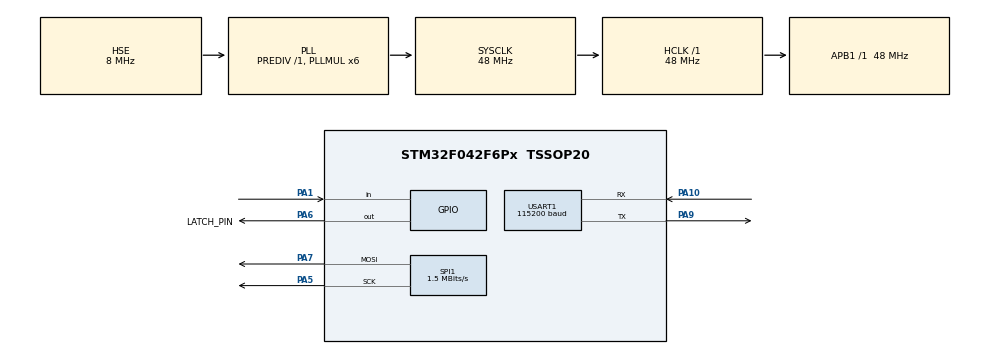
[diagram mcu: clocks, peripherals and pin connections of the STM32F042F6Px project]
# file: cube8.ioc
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Mcu.Family=STM32F0
Mcu.Name=STM32F042F6Px
Mcu.Package=TSSOP20
NVIC.USART1_IRQn=true\:0\:0\:false\:false\:true\:true\:true\:true
PA1.GPIO_PuPd=GPIO_PULLUP
PA1.Signal=GPIO_Input
PA10.Mode=Asynchronous
PA10.Signal=USART1_RX
PA13.Mode=Serial_Wire
PA13.Signal=SYS_SWDIO
PA14.Mode=Serial_Wire
PA14.Signal=SYS_SWCLK
PA5.Mode=TX_Only_Simplex_Unidirect_Master
PA5.Signal=SPI1_SCK
PA6.GPIO_Label=LATCH_PIN
PA6.GPIO_Speed=GPIO_SPEED_FREQ_HIGH
PA6.Signal=GPIO_Output
PA7.Mode=TX_Only_Simplex_Unidirect_Master
PA7.Signal=SPI1_MOSI
PA9.Mode=Asynchronous
PA9.Signal=USART1_TX
PF0-OSC_IN.Mode=HSE-External-Oscillator
PF0-OSC_IN.Signal=RCC_OSC_IN
PF1-OSC_OUT.Mode=HSE-External-Oscillator
PF1-OSC_OUT.Signal=RCC_OSC_OUT
ProjectManager.HeapSize=0x200
ProjectManager.StackSize=0x400
ProjectManager.TargetToolchain=STM32CubeIDE
RCC.AHBFreq_Value=48000000
RCC.APB1Freq_Value=48000000
RCC.APB1TimFreq_Value=48000000
RCC.HCLKFreq_Value=48000000
RCC.PLLMUL=RCC_PLL_MUL6
RCC.PLLSourceVirtual=RCC_PLLSOURCE_HSE
RCC.SYSCLKFreq_VALUE=48000000
RCC.SYSCLKSource=RCC_SYSCLKSOURCE_PLLCLK
SPI1.BaudRatePrescaler=SPI_BAUDRATEPRESCALER_32
SPI1.CalculateBaudRate=1.5 MBits/s
SPI1.DataSize=SPI_DATASIZE_8BIT
SPI1.Direction=SPI_DIRECTION_2LINES
SPI1.FirstBit=SPI_FIRSTBIT_MSB
SPI1.Mode=SPI_MODE_MASTER
SPI1.NSSPMode=SPI_NSS_PULSE_DISABLE
SPI1.VirtualType=VM_MASTER
USART1.BaudRate=115200
USART1.Mode=MODE_RX
USART1.VirtualMode=VM_ASYNC
board=custom

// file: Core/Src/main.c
#include "main.h"

/* USER CODE BEGIN Includes */

#include "led_cube_handle.h"
/* USER CODE END Includes */

/* USER CODE BEGIN PV */
SPI_HandleTypeDef hspi1;
UART_HandleTypeDef huart1;
uint8_t rxData;
Btn_Typedef button1;
/* USER CODE END PV */

void SystemClock_Config(void);
static void MX_GPIO_Init(void);
static void MX_SPI1_Init(void);
static void MX_USART1_UART_Init(void);
/* USER CODE BEGIN PFP */
void HAL_UART_RxCpltCallback(UART_HandleTypeDef *huart);
/* USER CODE END PFP */

/* USER CODE BEGIN 0 */
void HAL_UART_RxCpltCallback(UART_HandleTypeDef *huart)
{
	if (huart->Instance == huart1.Instance)
	{
		HAL_UART_Receive_IT(&huart1, &rxData, 1);
		currentEffect = rxData - 48;
	}
}
/* USER CODE END 0 */

int main(void)
{

  /* MCU Configuration--------------------------------------------------------*/

  /* Reset of all peripherals, Initializes the Flash interface and the Systick. */
  HAL_Init();

  /* USER CODE BEGIN Init */

  Btn_Init(&button1, GPIOA, GPIO_PIN_1);
  /* USER CODE END Init */

  /* Configure the system clock */
  SystemClock_Config();

  /* Initialize all configured peripherals */
  MX_GPIO_Init();
  MX_SPI1_Init();
  MX_USART1_UART_Init();
  /* USER CODE BEGIN 2 */
  HAL_UART_Receive_IT(&huart1,&rxData, 1);
  /* USER CODE END 2 */

  /* Infinite loop */
  while (1)
  {

    /* USER CODE BEGIN 3 */
	  Btn_Handle(&button1);
	  Led_cube_Handle(currentEffect);
//	  for (int i = 0; i < 8; i++)
//	  {
//		  for (int j = 0; j < 8; j++)
//		  {
//			  for (int k = 0; k < 8; k++)
//			  {
//				  DisplayLed(k, j, i, hspi1, 0);
//
//				  HAL_Delay(100);
//			  }
//		  }
//	  }
  }
  /* USER CODE END 3 */
}

void SystemClock_Config(void)
{
  RCC_OscInitTypeDef RCC_OscInitStruct = {0};
  RCC_ClkInitTypeDef RCC_ClkInitStruct = {0};
  RCC_PeriphCLKInitTypeDef PeriphClkInit = {0};

  /** Initializes the RCC Oscillators according to the specified parameters
  * in the RCC_OscInitTypeDef structure.
  */
  RCC_OscInitStruct.OscillatorType = RCC_OSCILLATORTYPE_HSE;
  RCC_OscInitStruct.HSEState = RCC_HSE_ON;
  RCC_OscInitStruct.PLL.PLLState = RCC_PLL_ON;
  RCC_OscInitStruct.PLL.PLLSource = RCC_PLLSOURCE_HSE;
  RCC_OscInitStruct.PLL.PLLMUL = RCC_PLL_MUL6;
  RCC_OscInitStruct.PLL.PREDIV = RCC_PREDIV_DIV1;
  if (HAL_RCC_OscConfig(&RCC_OscInitStruct) != HAL_OK)
  {
    Error_Handler();
  }

  /** Initializes the CPU, AHB and APB buses clocks
  */
  RCC_ClkInitStruct.ClockType = RCC_CLOCKTYPE_HCLK|RCC_CLOCKTYPE_SYSCLK
                              |RCC_CLOCKTYPE_PCLK1;
  RCC_ClkInitStruct.SYSCLKSource = RCC_SYSCLKSOURCE_PLLCLK;
  RCC_ClkInitStruct.AHBCLKDivider = RCC_SYSCLK_DIV1;
  RCC_ClkInitStruct.APB1CLKDivider = RCC_HCLK_DIV1;

  if (HAL_RCC_ClockConfig(&RCC_ClkInitStruct, FLASH_LATENCY_1) != HAL_OK)
  {
    Error_Handler();
  }
  PeriphClkInit.PeriphClockSelection = RCC_PERIPHCLK_USART1;
  PeriphClkInit.Usart1ClockSelection = RCC_USART1CLKSOURCE_PCLK1;
  if (HAL_RCCEx_PeriphCLKConfig(&PeriphClkInit) != HAL_OK)
  {
    Error_Handler();
  }
}

static void MX_SPI1_Init(void)
{

  /* SPI1 parameter configuration*/
  hspi1.Instance = SPI1;
  hspi1.Init.Mode = SPI_MODE_MASTER;
  hspi1.Init.Direction = SPI_DIRECTION_2LINES;
  hspi1.Init.DataSize = SPI_DATASIZE_8BIT;
  hspi1.Init.CLKPolarity = SPI_POLARITY_LOW;
  hspi1.Init.CLKPhase = SPI_PHASE_1EDGE;
  hspi1.Init.NSS = SPI_NSS_SOFT;
  hspi1.Init.BaudRatePrescaler = SPI_BAUDRATEPRESCALER_32;
  hspi1.Init.FirstBit = SPI_FIRSTBIT_MSB;
  hspi1.Init.TIMode = SPI_TIMODE_DISABLE;
  hspi1.Init.CRCCalculation = SPI_CRCCALCULATION_DISABLE;
  hspi1.Init.CRCPolynomial = 7;
  hspi1.Init.CRCLength = SPI_CRC_LENGTH_DATASIZE;
  hspi1.Init.NSSPMode = SPI_NSS_PULSE_DISABLE;
  if (HAL_SPI_Init(&hspi1) != HAL_OK)
  {
    Error_Handler();
  }

}

static void MX_USART1_UART_Init(void)
{

  huart1.Instance = USART1;
  huart1.Init.BaudRate = 115200;
  huart1.Init.WordLength = UART_WORDLENGTH_8B;
  huart1.Init.StopBits = UART_STOPBITS_1;
  huart1.Init.Parity = UART_PARITY_NONE;
  huart1.Init.Mode = UART_MODE_RX;
  huart1.Init.HwFlowCtl = UART_HWCONTROL_NONE;
  huart1.Init.OverSampling = UART_OVERSAMPLING_16;
  huart1.Init.OneBitSampling = UART_ONE_BIT_SAMPLE_DISABLE;
  huart1.AdvancedInit.AdvFeatureInit = UART_ADVFEATURE_NO_INIT;
  if (HAL_UART_Init(&huart1) != HAL_OK)
  {
    Error_Handler();
  }

}

static void MX_GPIO_Init(void)
{
  GPIO_InitTypeDef GPIO_InitStruct = {0};

  /* GPIO Ports Clock Enable */
  __HAL_RCC_GPIOF_CLK_ENABLE();
  __HAL_RCC_GPIOA_CLK_ENABLE();

  /*Configure GPIO pin Output Level */
  HAL_GPIO_WritePin(LATCH_PIN_GPIO_Port, LATCH_PIN_Pin, GPIO_PIN_RESET);

  /*Configure GPIO pin : PA1 */
  GPIO_InitStruct.Pin = GPIO_PIN_1;
  GPIO_InitStruct.Mode = GPIO_MODE_INPUT;
  GPIO_InitStruct.Pull = GPIO_PULLUP;
  HAL_GPIO_Init(GPIOA, &GPIO_InitStruct);

  /*Configure GPIO pin : LATCH_PIN_Pin */
  GPIO_InitStruct.Pin = LATCH_PIN_Pin;
  GPIO_InitStruct.Mode = GPIO_MODE_OUTPUT_PP;
  GPIO_InitStruct.Pull = GPIO_NOPULL;
  GPIO_InitStruct.Speed = GPIO_SPEED_FREQ_HIGH;
  HAL_GPIO_Init(LATCH_PIN_GPIO_Port, &GPIO_InitStruct);

}

void Error_Handler(void)
{
  __disable_irq();
  while (1)
  {
  }
}
